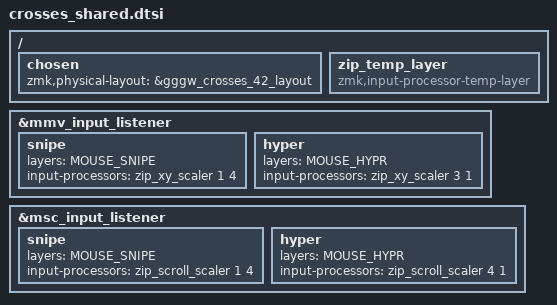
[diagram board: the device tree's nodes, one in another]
#define CONFIG_WIRELESS
#define REAL_POINTING_DEVICE
#define ZMK_BASE_LAYER(name, LT, RT, LM, RM, LB, RB, LH, RH)                   \
    ZMK_LAYER(                                                                 \
        name,                                                                  \
                 LT RT                                                         \
                 LM RM                                                         \
                 LB RB                                                         \
                 LH RH                                                         \
    )

#include <zmk-helpers/key-labels/42.h>

/ {
    chosen {
        zmk,physical-layout = &gggw_crosses_42_layout;
    };

    zip_temp_layer: zip_temp_layer {
        compatible = "zmk,input-processor-temp-layer";
        #input-processor-cells = <2>;
    };
};

#include "base.keymap"

&mmv_input_listener {
    snipe {
        layers = <MOUSE_SNIPE>;
        input-processors = <&zip_xy_scaler 1 4>;
    };

    hyper {
        layers = <MOUSE_HYPR>;
        input-processors = <&zip_xy_scaler 3 1>;
    };
};

&msc_input_listener {
    snipe {
        layers = <MOUSE_SNIPE>;
        input-processors = <&zip_scroll_scaler 1 4>;
    };

    hyper {
        layers = <MOUSE_HYPR>;
        input-processors = <&zip_scroll_scaler 4 1>;
    };
};
